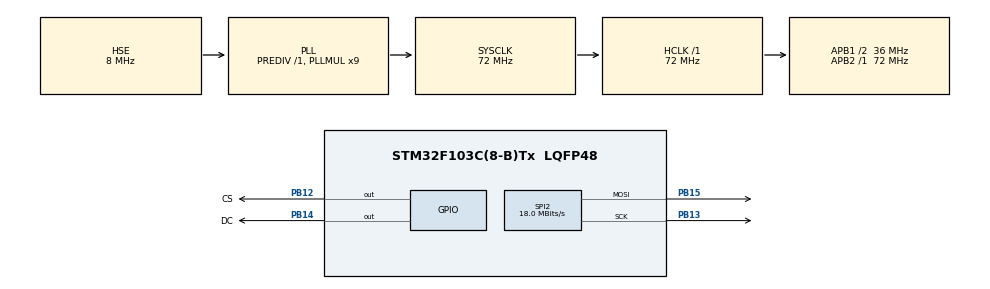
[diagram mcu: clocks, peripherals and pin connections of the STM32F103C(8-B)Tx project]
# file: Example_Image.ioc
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Mcu.Family=STM32F1
Mcu.Name=STM32F103C(8-B)Tx
Mcu.Package=LQFP48
NVIC.PriorityGroup=NVIC_PRIORITYGROUP_4
NVIC.TIM1_UP_IRQn=true\:0\:0\:false\:false\:true\:true\:true\:true
PA13.Mode=Serial_Wire
PA13.Signal=SYS_JTMS-SWDIO
PA14.Mode=Serial_Wire
PA14.Signal=SYS_JTCK-SWCLK
PB12.GPIO_Label=CS
PB12.Signal=GPIO_Output
PB13.Mode=TX_Only_Simplex_Unidirect_Master
PB13.Signal=SPI2_SCK
PB14.GPIO_Label=DC
PB14.Signal=GPIO_Output
PB15.Mode=TX_Only_Simplex_Unidirect_Master
PB15.Signal=SPI2_MOSI
PD0-OSC_IN.Mode=HSE-External-Oscillator
PD0-OSC_IN.Signal=RCC_OSC_IN
PD1-OSC_OUT.Mode=HSE-External-Oscillator
PD1-OSC_OUT.Signal=RCC_OSC_OUT
ProjectManager.HeapSize=0x200
ProjectManager.StackSize=0x400
ProjectManager.TargetToolchain=MDK-ARM V5.32
RCC.ADCPresc=RCC_ADCPCLK2_DIV6
RCC.AHBFreq_Value=72000000
RCC.APB1CLKDivider=RCC_HCLK_DIV2
RCC.APB1Freq_Value=36000000
RCC.APB1TimFreq_Value=72000000
RCC.APB2Freq_Value=72000000
RCC.APB2TimFreq_Value=72000000
RCC.HCLKFreq_Value=72000000
RCC.PLLMUL=RCC_PLL_MUL9
RCC.PLLSourceVirtual=RCC_PLLSOURCE_HSE
RCC.SYSCLKFreq_VALUE=72000000
RCC.SYSCLKSource=RCC_SYSCLKSOURCE_PLLCLK
RCC.USBFreq_Value=72000000
SPI2.CalculateBaudRate=18.0 MBits/s
SPI2.Direction=SPI_DIRECTION_2LINES
SPI2.Mode=SPI_MODE_MASTER
SPI2.VirtualType=VM_MASTER
TIM1.Period=999
TIM1.Prescaler=71
TIM2.Period=999
TIM2.Prescaler=71
VP_TIM1_VS_ClockSourceINT.Mode=Internal
VP_TIM2_VS_ClockSourceINT.Mode=Internal
board=custom

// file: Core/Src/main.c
/* USER CODE BEGIN Header */
/**
  ******************************************************************************
  * @file           : main.c
  * @brief          : Main program body
  ******************************************************************************
  * @attention
  *
  * Copyright (c) 2026 STMicroelectronics.
  * All rights reserved.
  *
  * This software is licensed under terms that can be found in the LICENSE file
  * in the root directory of this software component.
  * If no LICENSE file comes with this software, it is provided AS-IS.
  *
  ******************************************************************************
  */
/* USER CODE END Header */
#include "main.h"

/* USER CODE BEGIN Includes */
#include "Example_Image_Main.h"
/* USER CODE END Includes */

SPI_HandleTypeDef hspi2;

TIM_HandleTypeDef htim1;
TIM_HandleTypeDef htim2;

void SystemClock_Config(void);
static void MX_GPIO_Init(void);
static void MX_TIM1_Init(void);
static void MX_SPI2_Init(void);
static void MX_TIM2_Init(void);

int main(void)
{

  /* MCU Configuration--------------------------------------------------------*/

  /* Reset of all peripherals, Initializes the Flash interface and the Systick. */
  HAL_Init();

  /* Configure the system clock */
  SystemClock_Config();

  /* Initialize all configured peripherals */
  MX_GPIO_Init();
  MX_TIM1_Init();
  MX_SPI2_Init();
  MX_TIM2_Init();

  /* Infinite loop */
  /* USER CODE BEGIN WHILE */
  while (1)
  {
		EXAMPLE_IMAGE_MAIN();
    /* USER CODE END WHILE */

  }
}

void SystemClock_Config(void)
{
  RCC_OscInitTypeDef RCC_OscInitStruct = {0};
  RCC_ClkInitTypeDef RCC_ClkInitStruct = {0};

  /** Initializes the RCC Oscillators according to the specified parameters
  * in the RCC_OscInitTypeDef structure.
  */
  RCC_OscInitStruct.OscillatorType = RCC_OSCILLATORTYPE_HSE;
  RCC_OscInitStruct.HSEState = RCC_HSE_ON;
  RCC_OscInitStruct.HSEPredivValue = RCC_HSE_PREDIV_DIV1;
  RCC_OscInitStruct.HSIState = RCC_HSI_ON;
  RCC_OscInitStruct.PLL.PLLState = RCC_PLL_ON;
  RCC_OscInitStruct.PLL.PLLSource = RCC_PLLSOURCE_HSE;
  RCC_OscInitStruct.PLL.PLLMUL = RCC_PLL_MUL9;
  if (HAL_RCC_OscConfig(&RCC_OscInitStruct) != HAL_OK)
  {
    Error_Handler();
  }

  /** Initializes the CPU, AHB and APB buses clocks
  */
  RCC_ClkInitStruct.ClockType = RCC_CLOCKTYPE_HCLK|RCC_CLOCKTYPE_SYSCLK
                              |RCC_CLOCKTYPE_PCLK1|RCC_CLOCKTYPE_PCLK2;
  RCC_ClkInitStruct.SYSCLKSource = RCC_SYSCLKSOURCE_PLLCLK;
  RCC_ClkInitStruct.AHBCLKDivider = RCC_SYSCLK_DIV1;
  RCC_ClkInitStruct.APB1CLKDivider = RCC_HCLK_DIV2;
  RCC_ClkInitStruct.APB2CLKDivider = RCC_HCLK_DIV1;

  if (HAL_RCC_ClockConfig(&RCC_ClkInitStruct, FLASH_LATENCY_2) != HAL_OK)
  {
    Error_Handler();
  }
}

static void MX_SPI2_Init(void)
{

  /* SPI2 parameter configuration*/
  hspi2.Instance = SPI2;
  hspi2.Init.Mode = SPI_MODE_MASTER;
  hspi2.Init.Direction = SPI_DIRECTION_2LINES;
  hspi2.Init.DataSize = SPI_DATASIZE_8BIT;
  hspi2.Init.CLKPolarity = SPI_POLARITY_LOW;
  hspi2.Init.CLKPhase = SPI_PHASE_1EDGE;
  hspi2.Init.NSS = SPI_NSS_SOFT;
  hspi2.Init.BaudRatePrescaler = SPI_BAUDRATEPRESCALER_2;
  hspi2.Init.FirstBit = SPI_FIRSTBIT_MSB;
  hspi2.Init.TIMode = SPI_TIMODE_DISABLE;
  hspi2.Init.CRCCalculation = SPI_CRCCALCULATION_DISABLE;
  hspi2.Init.CRCPolynomial = 10;
  if (HAL_SPI_Init(&hspi2) != HAL_OK)
  {
    Error_Handler();
  }

}

static void MX_TIM1_Init(void)
{

  TIM_ClockConfigTypeDef sClockSourceConfig = {0};
  TIM_MasterConfigTypeDef sMasterConfig = {0};

  htim1.Instance = TIM1;
  htim1.Init.Prescaler = 71;
  htim1.Init.CounterMode = TIM_COUNTERMODE_UP;
  htim1.Init.Period = 999;
  htim1.Init.ClockDivision = TIM_CLOCKDIVISION_DIV1;
  htim1.Init.RepetitionCounter = 0;
  htim1.Init.AutoReloadPreload = TIM_AUTORELOAD_PRELOAD_DISABLE;
  if (HAL_TIM_Base_Init(&htim1) != HAL_OK)
  {
    Error_Handler();
  }
  sClockSourceConfig.ClockSource = TIM_CLOCKSOURCE_INTERNAL;
  if (HAL_TIM_ConfigClockSource(&htim1, &sClockSourceConfig) != HAL_OK)
  {
    Error_Handler();
  }
  sMasterConfig.MasterOutputTrigger = TIM_TRGO_RESET;
  sMasterConfig.MasterSlaveMode = TIM_MASTERSLAVEMODE_DISABLE;
  if (HAL_TIMEx_MasterConfigSynchronization(&htim1, &sMasterConfig) != HAL_OK)
  {
    Error_Handler();
  }

}

static void MX_TIM2_Init(void)
{

  TIM_ClockConfigTypeDef sClockSourceConfig = {0};
  TIM_MasterConfigTypeDef sMasterConfig = {0};

  htim2.Instance = TIM2;
  htim2.Init.Prescaler = 71;
  htim2.Init.CounterMode = TIM_COUNTERMODE_UP;
  htim2.Init.Period = 999;
  htim2.Init.ClockDivision = TIM_CLOCKDIVISION_DIV1;
  htim2.Init.AutoReloadPreload = TIM_AUTORELOAD_PRELOAD_DISABLE;
  if (HAL_TIM_Base_Init(&htim2) != HAL_OK)
  {
    Error_Handler();
  }
  sClockSourceConfig.ClockSource = TIM_CLOCKSOURCE_INTERNAL;
  if (HAL_TIM_ConfigClockSource(&htim2, &sClockSourceConfig) != HAL_OK)
  {
    Error_Handler();
  }
  sMasterConfig.MasterOutputTrigger = TIM_TRGO_RESET;
  sMasterConfig.MasterSlaveMode = TIM_MASTERSLAVEMODE_DISABLE;
  if (HAL_TIMEx_MasterConfigSynchronization(&htim2, &sMasterConfig) != HAL_OK)
  {
    Error_Handler();
  }

}

static void MX_GPIO_Init(void)
{
  GPIO_InitTypeDef GPIO_InitStruct = {0};

  /* GPIO Ports Clock Enable */
  __HAL_RCC_GPIOD_CLK_ENABLE();
  __HAL_RCC_GPIOB_CLK_ENABLE();
  __HAL_RCC_GPIOA_CLK_ENABLE();

  /*Configure GPIO pin Output Level */
  HAL_GPIO_WritePin(GPIOB, CS_Pin|DC_Pin, GPIO_PIN_RESET);

  /*Configure GPIO pins : CS_Pin DC_Pin */
  GPIO_InitStruct.Pin = CS_Pin|DC_Pin;
  GPIO_InitStruct.Mode = GPIO_MODE_OUTPUT_PP;
  GPIO_InitStruct.Pull = GPIO_NOPULL;
  GPIO_InitStruct.Speed = GPIO_SPEED_FREQ_LOW;
  HAL_GPIO_Init(GPIOB, &GPIO_InitStruct);

}

void Error_Handler(void)
{
  __disable_irq();
  while (1)
  {
  }
}
